AUTOSAR XML (schema 4.0)
package /ADAS_Components
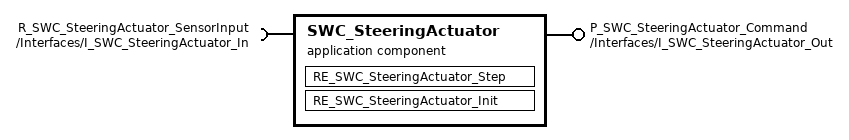
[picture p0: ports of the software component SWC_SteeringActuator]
  application sw component type SWC_SteeringActuator  # AUTOSAR Application SWC SWC_SteeringActuator for ADAS control sub-system
    provide port P_SWC_SteeringActuator_Command: provided-interface=/Interfaces/I_SWC_SteeringActuator_Out
    require port R_SWC_SteeringActuator_SensorInput: required-interface=/Interfaces/I_SWC_SteeringActuator_In
    behavior SWC_SteeringActuator_Behavior
      runnable RE_SWC_SteeringActuator_Step: symbol=SWC_SteeringActuator_Step
      runnable RE_SWC_SteeringActuator_Init: symbol=SWC_SteeringActuator_Init
  sender receiver interface I_SWC_SteeringActuator_Out  # Sender Receiver Interface for SWC_SteeringActuator outputs
    data DE_SWC_SteeringActuator_Signal: type=/AUTOSAR/Platform/uint32
  sender receiver interface I_SWC_SteeringActuator_In  # Sender Receiver Interface for SWC_SteeringActuator inputs
    data DE_SWC_SteeringActuator_RawData: type=/AUTOSAR/Platform/uint16
